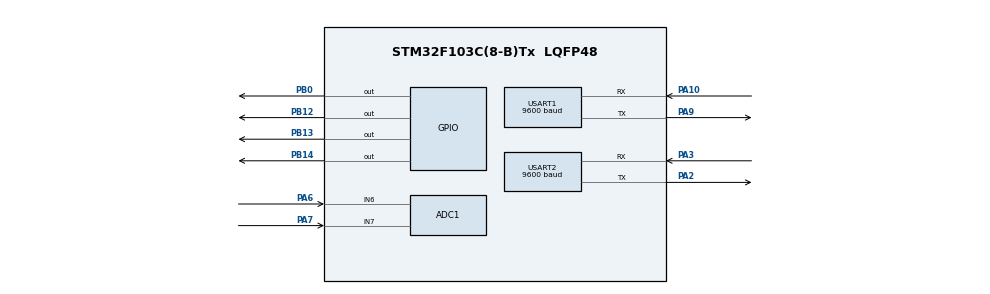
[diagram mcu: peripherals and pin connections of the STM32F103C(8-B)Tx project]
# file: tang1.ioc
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ADC1.Channel-3\#ChannelRegularConversion=ADC_CHANNEL_6
ADC1.Channel-4\#ChannelRegularConversion=ADC_CHANNEL_7
ADC1.ContinuousConvMode=ENABLE
ADC1.NbrOfConversion=2
ADC1.NbrOfConversionFlag=1
ADC1.Rank-3\#ChannelRegularConversion=1
ADC1.Rank-4\#ChannelRegularConversion=2
ADC1.SamplingTime-3\#ChannelRegularConversion=ADC_SAMPLETIME_239CYCLES_5
ADC1.SamplingTime-4\#ChannelRegularConversion=ADC_SAMPLETIME_239CYCLES_5
ADC1.master=1
Mcu.Family=STM32F1
Mcu.Name=STM32F103C(8-B)Tx
Mcu.Package=LQFP48
NVIC.PriorityGroup=NVIC_PRIORITYGROUP_4
NVIC.USART1_IRQn=true\:2\:0\:true\:false\:true\:true\:true\:true
NVIC.USART2_IRQn=true\:1\:0\:true\:false\:true\:true\:true\:true
PA10.Mode=Asynchronous
PA10.Signal=USART1_RX
PA13.Mode=Serial_Wire
PA13.Signal=SYS_JTMS-SWDIO
PA14.Mode=Serial_Wire
PA14.Signal=SYS_JTCK-SWCLK
PA2.Mode=Asynchronous
PA2.Signal=USART2_TX
PA3.Mode=Asynchronous
PA3.Signal=USART2_RX
PA6.Signal=ADCx_IN6
PA7.Signal=ADCx_IN7
PA9.Mode=Asynchronous
PA9.Signal=USART1_TX
PB0.Signal=GPIO_Output
PB12.Signal=GPIO_Output
PB13.Signal=GPIO_Output
PB14.Signal=GPIO_Output
ProjectManager.HeapSize=0x200
ProjectManager.StackSize=0x400
ProjectManager.TargetToolchain=MDK-ARM V5.32
RCC.APB1Freq_Value=8000000
RCC.APB2Freq_Value=8000000
SH.ADCx_IN6.0=ADC1_IN6,IN6
SH.ADCx_IN7.0=ADC1_IN7,IN7
USART1.BaudRate=9600
USART1.VirtualMode=VM_ASYNC
USART2.BaudRate=9600
USART2.VirtualMode=VM_ASYNC
board=custom

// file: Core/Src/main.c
/* USER CODE BEGIN Header */
/**
  ******************************************************************************
  * @file           : main.c
  * @brief          : Main program body
  ******************************************************************************
  * @attention
  *
  * Copyright (c) 2023 STMicroelectronics.
  * All rights reserved.
  *
  * This software is licensed under terms that can be found in the LICENSE file
  * in the root directory of this software component.
  * If no LICENSE file comes with this software, it is provided AS-IS.
  *
  ******************************************************************************
  */
/* USER CODE END Header */
#include "main.h"
#include "lcd_16x2.h"
#include "stdio.h"
#include "string.h"

ADC_HandleTypeDef hadc1;

UART_HandleTypeDef huart1;
UART_HandleTypeDef huart2;

void SystemClock_Config(void);
static void MX_GPIO_Init(void);
static void MX_ADC1_Init(void);
static void MX_USART1_UART_Init(void);
static void MX_USART2_UART_Init(void);

	char data_esp_rx[1];
	char data_hc05_tx[100];
	char data_hc05_rx[1];

	int adc_value_in6;
	int adc_value_in7;
	float rawVoltage_in6=0;
	float rawVoltage_in7=0;
	float current_in6=0;
	float current_in7=0;
	float sensitivity = 0.185;

	char buff[12];
	char buff1[12];
	void dkthietbi()
	{
		HAL_UART_Receive(&huart2,data_esp_rx,1,100);
		if(data_esp_rx[0]=='a')
		{
			HAL_GPIO_WritePin(GPIOB,GPIO_PIN_0,1);
		}

		if(data_esp_rx[0]=='b')
		{
			HAL_GPIO_WritePin(GPIOB,GPIO_PIN_0,0);
		}

		if(data_esp_rx[0]=='A')
		{
			HAL_GPIO_WritePin(GPIOB,GPIO_PIN_12,1);
			Lcd_gotoxy(5,0);
			Lcd_write_string("ON ");
		}

		if(data_esp_rx[0]=='B')
		{
			HAL_GPIO_WritePin(GPIOB,GPIO_PIN_12,0);
			Lcd_gotoxy(5,0);
			Lcd_write_string("OFF");
		}

		if(data_esp_rx[0]=='C')
		{
			HAL_GPIO_WritePin(GPIOB,GPIO_PIN_13,1);
			Lcd_gotoxy(13,0);
			Lcd_write_string("ON ");
		}

		if(data_esp_rx[0]=='D')
		{
			HAL_GPIO_WritePin(GPIOB,GPIO_PIN_13,0);
			Lcd_gotoxy(13,0);
			Lcd_write_string("OFF");
		}

		if(data_esp_rx[0]=='c')
		{	sprintf(data_hc05_tx,"A");
			HAL_UART_Transmit(&huart1,data_hc05_tx,strlen(data_hc05_tx),100);
		}

		if(data_esp_rx[0]=='d')
		{	sprintf(data_hc05_tx,"B");
			HAL_UART_Transmit(&huart1,data_hc05_tx,strlen(data_hc05_tx),100);
		}

		if(data_esp_rx[0]=='e')
		{	sprintf(data_hc05_tx,"C");
			HAL_UART_Transmit(&huart1,data_hc05_tx,strlen(data_hc05_tx),100);
		}

		if(data_esp_rx[0]=='f')
		{	sprintf(data_hc05_tx,"D");
			HAL_UART_Transmit(&huart1,data_hc05_tx,strlen(data_hc05_tx),100);
		}
	}
	void hienthilcd()
 {
	 Lcd_gotoxy(3,1);
	 sprintf(buff,"%.2f",current_in7);
	 Lcd_write_string(buff);

	 Lcd_gotoxy(11,1);
	 sprintf(buff1,"%.2f",current_in6);
	 Lcd_write_string(buff1);

 }
int main(void)
{

  /* MCU Configuration--------------------------------------------------------*/

  /* Reset of all peripherals, Initializes the Flash interface and the Systick. */
  HAL_Init();

  /* Configure the system clock */
  SystemClock_Config();

  /* Initialize all configured peripherals */
  MX_GPIO_Init();
  MX_ADC1_Init();
  MX_USART1_UART_Init();
  MX_USART2_UART_Init();
  /* USER CODE BEGIN 2 */
	HAL_Delay(500);
	Lcd_Init();
  /* USER CODE END 2 */

  /* Infinite loop */
  /* USER CODE BEGIN WHILE */
	HAL_GPIO_WritePin(GPIOB,GPIO_PIN_0,1);
	Lcd_gotoxy(2,0);
	Lcd_write_string("D1:");
	Lcd_gotoxy(5,0);
	Lcd_write_string("OFF");
	Lcd_gotoxy(10,0);
	Lcd_write_string("Q1:");
	Lcd_gotoxy(13,0);
	Lcd_write_string("OFF");
	Lcd_gotoxy(0,1);
	Lcd_write_string("A:");

  while (1)
  {
    /* USER CODE END WHILE */
		HAL_ADC_Start(&hadc1);
		HAL_ADC_PollForConversion(&hadc1,20);
		adc_value_in6=HAL_ADC_GetValue(&hadc1);
		HAL_ADC_PollForConversion(&hadc1,20);
		adc_value_in7=HAL_ADC_GetValue(&hadc1);
		HAL_ADC_Stop(&hadc1);
		rawVoltage_in6 = ((float)adc_value_in6/4095)*3.3*1.00008791;
		rawVoltage_in7 = ((float)adc_value_in7/4095)*3.3*1.00008791;
    current_in6 =(rawVoltage_in6 - 2.5)/sensitivity;
		current_in7 =(rawVoltage_in7 - 2.5)/sensitivity;
		hienthilcd();
		HAL_Delay(500);
		dkthietbi();
  }
}

void SystemClock_Config(void)
{
  RCC_OscInitTypeDef RCC_OscInitStruct = {0};
  RCC_ClkInitTypeDef RCC_ClkInitStruct = {0};
  RCC_PeriphCLKInitTypeDef PeriphClkInit = {0};

  /** Initializes the RCC Oscillators according to the specified parameters
  * in the RCC_OscInitTypeDef structure.
  */
  RCC_OscInitStruct.OscillatorType = RCC_OSCILLATORTYPE_HSI;
  RCC_OscInitStruct.HSIState = RCC_HSI_ON;
  RCC_OscInitStruct.HSICalibrationValue = RCC_HSICALIBRATION_DEFAULT;
  RCC_OscInitStruct.PLL.PLLState = RCC_PLL_NONE;
  if (HAL_RCC_OscConfig(&RCC_OscInitStruct) != HAL_OK)
  {
    Error_Handler();
  }

  /** Initializes the CPU, AHB and APB buses clocks
  */
  RCC_ClkInitStruct.ClockType = RCC_CLOCKTYPE_HCLK|RCC_CLOCKTYPE_SYSCLK
                              |RCC_CLOCKTYPE_PCLK1|RCC_CLOCKTYPE_PCLK2;
  RCC_ClkInitStruct.SYSCLKSource = RCC_SYSCLKSOURCE_HSI;
  RCC_ClkInitStruct.AHBCLKDivider = RCC_SYSCLK_DIV1;
  RCC_ClkInitStruct.APB1CLKDivider = RCC_HCLK_DIV1;
  RCC_ClkInitStruct.APB2CLKDivider = RCC_HCLK_DIV1;

  if (HAL_RCC_ClockConfig(&RCC_ClkInitStruct, FLASH_LATENCY_0) != HAL_OK)
  {
    Error_Handler();
  }
  PeriphClkInit.PeriphClockSelection = RCC_PERIPHCLK_ADC;
  PeriphClkInit.AdcClockSelection = RCC_ADCPCLK2_DIV2;
  if (HAL_RCCEx_PeriphCLKConfig(&PeriphClkInit) != HAL_OK)
  {
    Error_Handler();
  }
}

static void MX_ADC1_Init(void)
{

  ADC_ChannelConfTypeDef sConfig = {0};

  /** Common config
  */
  hadc1.Instance = ADC1;
  hadc1.Init.ScanConvMode = ADC_SCAN_ENABLE;
  hadc1.Init.ContinuousConvMode = ENABLE;
  hadc1.Init.DiscontinuousConvMode = DISABLE;
  hadc1.Init.ExternalTrigConv = ADC_SOFTWARE_START;
  hadc1.Init.DataAlign = ADC_DATAALIGN_RIGHT;
  hadc1.Init.NbrOfConversion = 2;
  if (HAL_ADC_Init(&hadc1) != HAL_OK)
  {
    Error_Handler();
  }

  /** Configure Regular Channel
  */
  sConfig.Channel = ADC_CHANNEL_6;
  sConfig.Rank = ADC_REGULAR_RANK_1;
  sConfig.SamplingTime = ADC_SAMPLETIME_239CYCLES_5;
  if (HAL_ADC_ConfigChannel(&hadc1, &sConfig) != HAL_OK)
  {
    Error_Handler();
  }

  /** Configure Regular Channel
  */
  sConfig.Channel = ADC_CHANNEL_7;
  sConfig.Rank = ADC_REGULAR_RANK_2;
  if (HAL_ADC_ConfigChannel(&hadc1, &sConfig) != HAL_OK)
  {
    Error_Handler();
  }

}

static void MX_USART1_UART_Init(void)
{

  huart1.Instance = USART1;
  huart1.Init.BaudRate = 9600;
  huart1.Init.WordLength = UART_WORDLENGTH_8B;
  huart1.Init.StopBits = UART_STOPBITS_1;
  huart1.Init.Parity = UART_PARITY_NONE;
  huart1.Init.Mode = UART_MODE_TX_RX;
  huart1.Init.HwFlowCtl = UART_HWCONTROL_NONE;
  huart1.Init.OverSampling = UART_OVERSAMPLING_16;
  if (HAL_UART_Init(&huart1) != HAL_OK)
  {
    Error_Handler();
  }

}

static void MX_USART2_UART_Init(void)
{

  huart2.Instance = USART2;
  huart2.Init.BaudRate = 9600;
  huart2.Init.WordLength = UART_WORDLENGTH_8B;
  huart2.Init.StopBits = UART_STOPBITS_1;
  huart2.Init.Parity = UART_PARITY_NONE;
  huart2.Init.Mode = UART_MODE_TX_RX;
  huart2.Init.HwFlowCtl = UART_HWCONTROL_NONE;
  huart2.Init.OverSampling = UART_OVERSAMPLING_16;
  if (HAL_UART_Init(&huart2) != HAL_OK)
  {
    Error_Handler();
  }

}

static void MX_GPIO_Init(void)
{
  GPIO_InitTypeDef GPIO_InitStruct = {0};

  /* GPIO Ports Clock Enable */
  __HAL_RCC_GPIOA_CLK_ENABLE();
  __HAL_RCC_GPIOB_CLK_ENABLE();

  /*Configure GPIO pin Output Level */
  HAL_GPIO_WritePin(GPIOB, GPIO_PIN_0|GPIO_PIN_12|GPIO_PIN_13|GPIO_PIN_14, GPIO_PIN_RESET);

  /*Configure GPIO pins : PB0 PB12 PB13 PB14 */
  GPIO_InitStruct.Pin = GPIO_PIN_0|GPIO_PIN_12|GPIO_PIN_13|GPIO_PIN_14;
  GPIO_InitStruct.Mode = GPIO_MODE_OUTPUT_PP;
  GPIO_InitStruct.Pull = GPIO_NOPULL;
  GPIO_InitStruct.Speed = GPIO_SPEED_FREQ_LOW;
  HAL_GPIO_Init(GPIOB, &GPIO_InitStruct);

}

void Error_Handler(void)
{
  __disable_irq();
  while (1)
  {
  }
}
